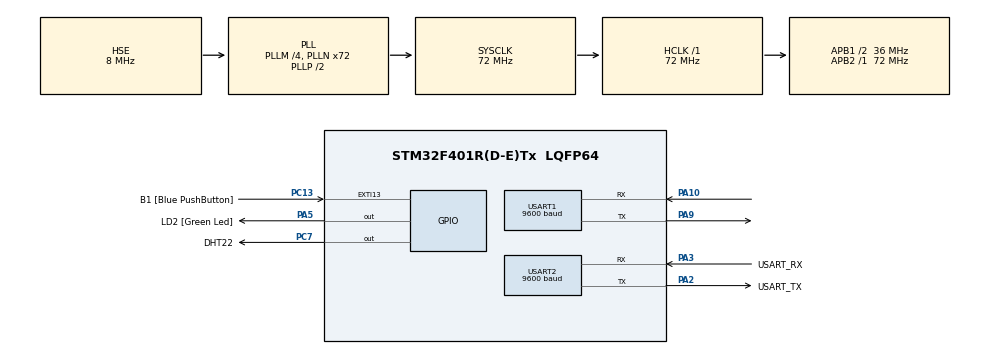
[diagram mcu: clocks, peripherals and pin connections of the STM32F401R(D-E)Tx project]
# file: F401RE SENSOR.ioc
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Mcu.Family=STM32F4
Mcu.Name=STM32F401R(D-E)Tx
Mcu.Package=LQFP64
NVIC.PriorityGroup=NVIC_PRIORITYGROUP_0
PA10.GPIO_Speed=GPIO_SPEED_FREQ_HIGH
PA10.Mode=Asynchronous
PA10.Signal=USART1_RX
PA13.GPIO_Label=TMS
PA13.Mode=Serial_Wire
PA13.Signal=SYS_JTMS-SWDIO
PA14.GPIO_Label=TCK
PA14.Mode=Serial_Wire
PA14.Signal=SYS_JTCK-SWCLK
PA2.GPIO_Label=USART_TX
PA2.GPIO_Mode=GPIO_MODE_AF_PP
PA2.GPIO_PuPd=GPIO_NOPULL
PA2.GPIO_Speed=GPIO_SPEED_FREQ_HIGH
PA2.Mode=Asynchronous
PA2.Signal=USART2_TX
PA3.GPIO_Label=USART_RX
PA3.GPIO_Mode=GPIO_MODE_AF_PP
PA3.GPIO_PuPd=GPIO_NOPULL
PA3.GPIO_Speed=GPIO_SPEED_FREQ_HIGH
PA3.Mode=Asynchronous
PA3.Signal=USART2_RX
PA5.GPIO_Label=LD2 [Green Led]
PA5.GPIO_Mode=GPIO_MODE_OUTPUT_PP
PA5.GPIO_PuPd=GPIO_NOPULL
PA5.GPIO_Speed=GPIO_SPEED_FREQ_LOW
PA5.Signal=GPIO_Output
PA9.GPIO_Speed=GPIO_SPEED_FREQ_HIGH
PA9.Mode=Asynchronous
PA9.Signal=USART1_TX
PB3.GPIO_Label=SWO
PB3.Signal=SYS_JTDO-SWO
PC13-ANTI_TAMP.GPIO_Label=B1 [Blue PushButton]
PC13-ANTI_TAMP.GPIO_ModeDefaultEXTI=GPIO_MODE_IT_FALLING
PC13-ANTI_TAMP.GPIO_PuPd=GPIO_NOPULL
PC13-ANTI_TAMP.Signal=GPXTI13
PC14-OSC32_IN.Signal=RCC_OSC32_IN
PC15-OSC32_OUT.Signal=RCC_OSC32_OUT
PC7.GPIO_Label=DHT22
PC7.Signal=GPIO_Output
PH0\ -\ OSC_IN.Mode=HSE-External-Oscillator
PH0\ -\ OSC_IN.Signal=RCC_OSC_IN
PH1\ -\ OSC_OUT.Mode=HSE-External-Oscillator
PH1\ -\ OSC_OUT.Signal=RCC_OSC_OUT
ProjectManager.HeapSize=0x200
ProjectManager.StackSize=0x400
ProjectManager.TargetToolchain=STM32CubeIDE
RCC.48MHZClocksFreq_Value=20571428.57142857
RCC.AHBFreq_Value=72000000
RCC.APB1CLKDivider=RCC_HCLK_DIV2
RCC.APB1Freq_Value=36000000
RCC.APB1TimFreq_Value=72000000
RCC.APB2Freq_Value=72000000
RCC.APB2TimFreq_Value=72000000
RCC.CortexFreq_Value=72000000
RCC.HCLKFreq_Value=72000000
RCC.HSE_VALUE=8000000
RCC.HSI_VALUE=16000000
RCC.LSE_VALUE=32768
RCC.PLLM=4
RCC.PLLN=72
RCC.PLLQ=7
RCC.PLLSourceVirtual=RCC_PLLSOURCE_HSE
RCC.SYSCLKFreq_VALUE=72000000
RCC.SYSCLKSource=RCC_SYSCLKSOURCE_PLLCLK
RCC.VCOOutputFreq_Value=144000000
TIM2.Period=65535
TIM2.Prescaler=71
USART1.BaudRate=9600
USART1.VirtualMode=VM_ASYNC
USART2.BaudRate=9600
USART2.VirtualMode=VM_ASYNC
VP_TIM2_VS_ClockSourceINT.Mode=Internal
board=NUCLEO-F401RE

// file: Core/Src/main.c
/* USER CODE BEGIN Header */
/**
  ******************************************************************************
  * @file           : main.c
  * @brief          : Main program body
  ******************************************************************************
  * @attention
  *
  * Copyright (c) 2023 STMicroelectronics.
  * All rights reserved.
  *
  * This software is licensed under terms that can be found in the LICENSE file
  * in the root directory of this software component.
  * If no LICENSE file comes with this software, it is provided AS-IS.
  *
  ******************************************************************************
  */
/* USER CODE END Header */
#include "main.h"
#include "dht22.h"
#include "temperature.h"
#include "tim.h"
#include "usart.h"
#include "gpio.h"

#include <stdio.h>
#include <string.h>
#include <stdbool.h>

void SystemClock_Config(void);

/* USER CODE BEGIN 0 */
// Simulated sensor values (replace with actual sensor readings)
uint8_t RH1, RH2, TC1, TC2, SUM, CHECK;
float tCelsius;
float tCelsius = 0.0;
/* USER CODE END 0 */

int main(void)
{

  /* MCU Configuration--------------------------------------------------------*/

  /* Reset of all peripherals, Initializes the Flash interface and the Systick. */
  HAL_Init();

  /* Configure the system clock */
  SystemClock_Config();

  /* Initialize all configured peripherals */
  MX_GPIO_Init();
  MX_USART2_UART_Init();
  MX_TIM2_Init();
  MX_USART1_UART_Init();
  /* USER CODE BEGIN 2 */
  HAL_TIM_Base_Start(&htim2);

  bool buttonPressed = false;
  bool programStarted = false;
  uint32_t pressStartTime = 0;
  uint32_t lastTransmissionTime = 0;
  /* USER CODE END 2 */

  /* Infinite loop */
  /* USER CODE BEGIN WHILE */
  while (1)
  {
    // Check if the button is pressed
    if (HAL_GPIO_ReadPin(B1_GPIO_Port, B1_Pin) == GPIO_PIN_RESET && !buttonPressed)
    {
      buttonPressed = true;
      pressStartTime = HAL_GetTick();
    }
    else if (HAL_GPIO_ReadPin(B1_GPIO_Port, B1_Pin) == GPIO_PIN_SET && buttonPressed)
    {
      buttonPressed = false;

      // Check if button was pressed for a certain time (e.g., 500ms)
      if (HAL_GetTick() - pressStartTime >= 500)
      {
        programStarted = !programStarted; // Toggle program state
        if (programStarted)
        {
          char startMessage[] = "Inicio del programa\r\n";
          HAL_UART_Transmit(&huart2, (uint8_t *)startMessage, strlen(startMessage), HAL_MAX_DELAY);
        }
      }
    }

    if (programStarted && (HAL_GetTick() - lastTransmissionTime >= 10000))
    {
      lastTransmissionTime = HAL_GetTick();

      if (DHT22_Start())
      {
        RH1 = DHT22_Read(); // First 8bits of humidity
        RH2 = DHT22_Read(); // Second 8bits of Relative humidity
        TC1 = DHT22_Read(); // First 8bits of Celsius
        TC2 = DHT22_Read(); // Second 8bits of Celsius
        SUM = DHT22_Read(); // Check sum
        CHECK = RH1 + RH2 + TC1 + TC2;

        if (CHECK == SUM)
        {
          tCelsius = convertToCelsius(TC1, TC2);

          // Convert temperature value to string
          char tempString[10];
          sprintf(tempString, "%.2f", tCelsius);

          // Transmit temperature value followed by a newline character
          HAL_UART_Transmit(&huart1, (uint8_t *)tempString, strlen(tempString), 100);
          HAL_UART_Transmit(&huart1, (uint8_t *)"\r\n", 2, 100); // Transmit newline

          HAL_UART_Transmit(&huart2, (uint8_t *)tempString, strlen(tempString), 100);
          HAL_UART_Transmit(&huart2, (uint8_t *)"\r\n", 2, 100); // Transmit newline
        }
      }
    }

    HAL_Delay(200);
  }
}

void SystemClock_Config(void)
{
  RCC_OscInitTypeDef RCC_OscInitStruct = {0};
  RCC_ClkInitTypeDef RCC_ClkInitStruct = {0};

  /** Configure the main internal regulator output voltage
  */
  __HAL_RCC_PWR_CLK_ENABLE();
  __HAL_PWR_VOLTAGESCALING_CONFIG(PWR_REGULATOR_VOLTAGE_SCALE2);

  /** Initializes the RCC Oscillators according to the specified parameters
  * in the RCC_OscInitTypeDef structure.
  */
  RCC_OscInitStruct.OscillatorType = RCC_OSCILLATORTYPE_HSE;
  RCC_OscInitStruct.HSEState = RCC_HSE_ON;
  RCC_OscInitStruct.PLL.PLLState = RCC_PLL_ON;
  RCC_OscInitStruct.PLL.PLLSource = RCC_PLLSOURCE_HSE;
  RCC_OscInitStruct.PLL.PLLM = 4;
  RCC_OscInitStruct.PLL.PLLN = 72;
  RCC_OscInitStruct.PLL.PLLP = RCC_PLLP_DIV2;
  RCC_OscInitStruct.PLL.PLLQ = 7;
  if (HAL_RCC_OscConfig(&RCC_OscInitStruct) != HAL_OK)
  {
    Error_Handler();
  }

  /** Initializes the CPU, AHB and APB buses clocks
  */
  RCC_ClkInitStruct.ClockType = RCC_CLOCKTYPE_HCLK|RCC_CLOCKTYPE_SYSCLK
                              |RCC_CLOCKTYPE_PCLK1|RCC_CLOCKTYPE_PCLK2;
  RCC_ClkInitStruct.SYSCLKSource = RCC_SYSCLKSOURCE_PLLCLK;
  RCC_ClkInitStruct.AHBCLKDivider = RCC_SYSCLK_DIV1;
  RCC_ClkInitStruct.APB1CLKDivider = RCC_HCLK_DIV2;
  RCC_ClkInitStruct.APB2CLKDivider = RCC_HCLK_DIV1;

  if (HAL_RCC_ClockConfig(&RCC_ClkInitStruct, FLASH_LATENCY_2) != HAL_OK)
  {
    Error_Handler();
  }
}

void Error_Handler(void)
{
  __disable_irq();
  while (1)
  {
  }
}
